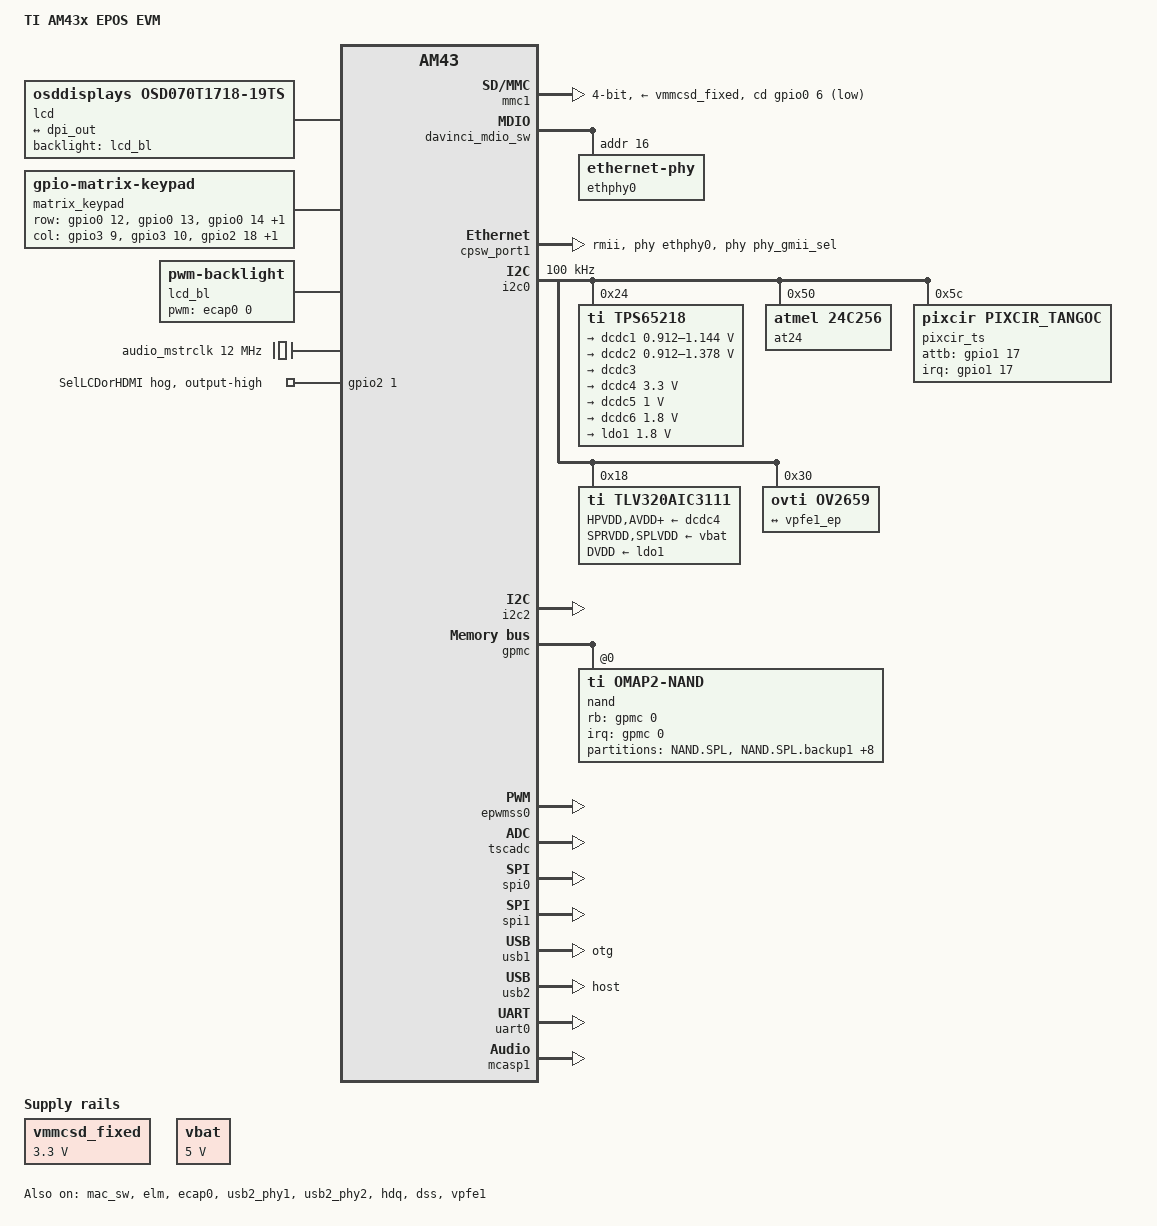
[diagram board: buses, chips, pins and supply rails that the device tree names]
/dts-v1/;
#include "am4372.dtsi"
#include <dt-bindings/pinctrl/am43xx.h>
#include <dt-bindings/gpio/gpio.h>
#include <dt-bindings/pwm/pwm.h>
#include <dt-bindings/sound/tlv320aic31xx.h>
/ {
	model = "TI AM43x EPOS EVM";
	compatible = "ti,am43x-epos-evm","ti,am438x","ti,am43";
	aliases {
		display0 = &lcd0;
	};
	chosen {
		stdout-path = &uart0;
	};
	vmmcsd_fixed: fixedregulator-sd {
		compatible = "regulator-fixed";
		regulator-name = "vmmcsd_fixed";
		regulator-min-microvolt = <3300000>;
		regulator-max-microvolt = <3300000>;
		enable-active-high;
	};
	vbat: fixedregulator0 {
		compatible = "regulator-fixed";
		regulator-name = "vbat";
		regulator-min-microvolt = <5000000>;
		regulator-max-microvolt = <5000000>;
		regulator-boot-on;
	};
	lcd0: display {
		compatible = "osddisplays,osd070t1718-19ts", "panel-dpi";
		label = "lcd";
		backlight = <&lcd_bl>;
		port {
			lcd_in: endpoint {
				remote-endpoint = <&dpi_out>;
			};
		};
	};
	matrix_keypad: matrix_keypad0 {
		compatible = "gpio-matrix-keypad";
		debounce-delay-ms = <5>;
		col-scan-delay-us = <2>;
		pinctrl-names = "default", "sleep";
		pinctrl-0 = <&matrix_keypad_default>;
		pinctrl-1 = <&matrix_keypad_sleep>;
		wakeup-source;
		row-gpios = <&gpio0 12 GPIO_ACTIVE_HIGH		 
			     &gpio0 13 GPIO_ACTIVE_HIGH		 
			     &gpio0 14 GPIO_ACTIVE_HIGH		 
			     &gpio0 15 GPIO_ACTIVE_HIGH>;	 
		col-gpios = <&gpio3 9 GPIO_ACTIVE_HIGH		 
			     &gpio3 10 GPIO_ACTIVE_HIGH		 
			     &gpio2 18 GPIO_ACTIVE_HIGH		 
			     &gpio2 19 GPIO_ACTIVE_HIGH>;	 
		linux,keymap = <0x00000201	 
			0x01000204	 
			0x02000207	 
			0x0300020a	 
			0x00010202	 
			0x01010205	 
			0x02010208	 
			0x03010200	 
			0x00020203	 
			0x01020206	 
			0x02020209	 
			0x0302020b	 
			0x00030067	 
			0x0103006a	 
			0x0203006c	 
			0x03030069>;	 
	};
	lcd_bl: backlight {
		compatible = "pwm-backlight";
		pwms = <&ecap0 0 50000 PWM_POLARITY_INVERTED>;
		brightness-levels = <0 51 53 56 62 75 101 152 255>;
		default-brightness-level = <8>;
	};
	sound0: sound0 {
		compatible = "simple-audio-card";
		simple-audio-card,name = "AM43-EPOS-EVM";
		simple-audio-card,widgets =
			"Microphone", "Microphone Jack",
			"Headphone", "Headphone Jack",
			"Speaker", "Speaker";
		simple-audio-card,routing =
			"MIC1LP", "Microphone Jack",
			"MIC1RP", "Microphone Jack",
			"MIC1LP", "MICBIAS",
			"MIC1RP", "MICBIAS",
			"Headphone Jack", "HPL",
			"Headphone Jack", "HPR",
			"Speaker", "SPL",
			"Speaker", "SPR";
		simple-audio-card,format = "dsp_b";
		simple-audio-card,bitclock-master = <&sound0_master>;
		simple-audio-card,frame-master = <&sound0_master>;
		simple-audio-card,bitclock-inversion;
		simple-audio-card,cpu {
			sound-dai = <&mcasp1>;
			system-clock-frequency = <12000000>;
		};
		sound0_master: simple-audio-card,codec {
			sound-dai = <&tlv320aic3111>;
			system-clock-frequency = <12000000>;
		};
	};
	audio_mstrclk: clock {
		compatible = "fixed-clock";
		#clock-cells = <0>;
		clock-frequency = <12000000>;
	};
};
&am43xx_pinmux {
		pinctrl-names = "default";
		pinctrl-0 = <&unused_pins>;
		unused_pins: unused-pins {
			pinctrl-single,pins = <
				AM4372_IOPAD(0x848, DS0_PIN_OUTPUT_PULLUP | PIN_OUTPUT_PULLUP | MUX_MODE7)
				AM4372_IOPAD(0x850, DS0_PIN_INPUT | PIN_INPUT_PULLDOWN | MUX_MODE7)
				AM4372_IOPAD(0x858, DS0_PIN_INPUT | PIN_INPUT_PULLDOWN | MUX_MODE7)
				AM4372_IOPAD(0x860, DS0_PIN_INPUT | PIN_INPUT_PULLDOWN | MUX_MODE7)
				AM4372_IOPAD(0x864, DS0_PIN_INPUT | PIN_INPUT_PULLDOWN | MUX_MODE7)
				AM4372_IOPAD(0x868, DS0_PIN_INPUT | PIN_INPUT_PULLDOWN | MUX_MODE7)
				AM4372_IOPAD(0x86c, DS0_PIN_INPUT | PIN_INPUT_PULLDOWN | MUX_MODE7)
				AM4372_IOPAD(0x878, DS0_PIN_OUTPUT_PULLUP | PIN_OUTPUT_PULLUP | MUX_MODE7)
				AM4372_IOPAD(0x908, DS0_PIN_INPUT_PULLDOWN | PIN_INPUT_PULLDOWN | MUX_MODE7)
				AM4372_IOPAD(0x91c, DS0_PIN_OUTPUT_PULLDOWN | PIN_OUTPUT_PULLDOWN | MUX_MODE7)
				AM4372_IOPAD(0x920, DS0_PIN_INPUT | PIN_INPUT_PULLDOWN | MUX_MODE7)
				AM4372_IOPAD(0x9e0, DS0_PIN_INPUT_PULLDOWN | PIN_INPUT_PULLDOWN | MUX_MODE7)
				AM4372_IOPAD(0xA0c, DS0_PIN_OUTPUT_PULLDOWN | PIN_OUTPUT_PULLDOWN | MUX_MODE7)
				AM4372_IOPAD(0xA38, DS0_PIN_INPUT | PIN_INPUT_PULLDOWN | MUX_MODE7)
				AM4372_IOPAD(0xA3c, DS0_PIN_INPUT | PIN_INPUT_PULLDOWN | MUX_MODE7)
				AM4372_IOPAD(0xA40, DS0_PIN_INPUT | PIN_INPUT_PULLDOWN | MUX_MODE7)
				AM4372_IOPAD(0xA44, DS0_PIN_INPUT | PIN_INPUT_PULLDOWN | MUX_MODE7)
				AM4372_IOPAD(0xA48, DS0_PIN_INPUT | PIN_INPUT_PULLDOWN | MUX_MODE7)
				AM4372_IOPAD(0xA4c, DS0_PIN_INPUT | PIN_INPUT_PULLDOWN | MUX_MODE7)
				AM4372_IOPAD(0xA50, DS0_PIN_INPUT | PIN_INPUT_PULLDOWN | MUX_MODE7)
				AM4372_IOPAD(0xA54, DS0_PIN_INPUT | PIN_INPUT_PULLDOWN | MUX_MODE7)
				AM4372_IOPAD(0xA58, DS0_PIN_INPUT | PIN_INPUT_PULLDOWN | MUX_MODE7)
				AM4372_IOPAD(0xA5c, DS0_PIN_INPUT | PIN_INPUT_PULLDOWN | MUX_MODE7)
				AM4372_IOPAD(0xA60, DS0_PIN_INPUT | PIN_INPUT_PULLDOWN | MUX_MODE7)
				AM4372_IOPAD(0xA64, DS0_PIN_OUTPUT_PULLUP | PIN_OUTPUT_PULLUP | MUX_MODE7)
				AM4372_IOPAD(0xA68, DS0_PIN_INPUT | PIN_INPUT_PULLDOWN | MUX_MODE7)
				AM4372_IOPAD(0xA6C, DS0_PIN_INPUT | PIN_INPUT_PULLDOWN | MUX_MODE7)
				AM4372_IOPAD(0xA74, DS0_PIN_INPUT_PULLDOWN | PIN_INPUT_PULLDOWN | MUX_MODE7)
				AM4372_IOPAD(0xA78, DS0_PIN_INPUT | PIN_INPUT_PULLDOWN | MUX_MODE7)
			>;
		};
		cpsw_default: cpsw-default-pins {
			pinctrl-single,pins = <
				AM4372_IOPAD(0x90c, PIN_INPUT_PULLDOWN | MUX_MODE1)	 
				AM4372_IOPAD(0x910, PIN_INPUT_PULLDOWN | MUX_MODE1)	 
				AM4372_IOPAD(0x914, PIN_OUTPUT_PULLDOWN | MUX_MODE1)	 
				AM4372_IOPAD(0x918, PIN_INPUT_PULLDOWN | MUX_MODE1)	 
				AM4372_IOPAD(0x924, PIN_OUTPUT_PULLDOWN | MUX_MODE1)	 
				AM4372_IOPAD(0x928, PIN_OUTPUT_PULLDOWN | MUX_MODE1)	 
				AM4372_IOPAD(0x93c, PIN_INPUT_PULLDOWN | MUX_MODE1)	 
				AM4372_IOPAD(0x940, PIN_INPUT_PULLDOWN | MUX_MODE1)	 
				AM4372_IOPAD(0x944, PIN_INPUT_PULLDOWN | MUX_MODE0)	 
			>;
		};
		cpsw_sleep: cpsw-sleep-pins {
			pinctrl-single,pins = <
				AM4372_IOPAD(0x90c, PIN_INPUT_PULLDOWN | MUX_MODE7)
				AM4372_IOPAD(0x910, PIN_INPUT_PULLDOWN | MUX_MODE7)
				AM4372_IOPAD(0x914, PIN_INPUT_PULLDOWN | MUX_MODE7)
				AM4372_IOPAD(0x918, PIN_INPUT_PULLDOWN | MUX_MODE7)
				AM4372_IOPAD(0x924, PIN_INPUT_PULLDOWN | MUX_MODE7)
				AM4372_IOPAD(0x928, PIN_INPUT_PULLDOWN | MUX_MODE7)
				AM4372_IOPAD(0x93c, PIN_INPUT_PULLDOWN | MUX_MODE7)
				AM4372_IOPAD(0x940, PIN_INPUT_PULLDOWN | MUX_MODE7)
				AM4372_IOPAD(0x944, PIN_INPUT_PULLDOWN | MUX_MODE7)
			>;
		};
		davinci_mdio_default: davinci-mdio-default-pins {
			pinctrl-single,pins = <
				AM4372_IOPAD(0x948, PIN_INPUT_PULLUP | SLEWCTRL_FAST | MUX_MODE0)	 
				AM4372_IOPAD(0x94c, PIN_OUTPUT_PULLUP | MUX_MODE0)			 
			>;
		};
		davinci_mdio_sleep: davinci-mdio-sleep-pins {
			pinctrl-single,pins = <
				AM4372_IOPAD(0x948, PIN_INPUT_PULLDOWN | MUX_MODE7)
				AM4372_IOPAD(0x94c, PIN_INPUT_PULLDOWN | MUX_MODE7)
			>;
		};
		i2c0_pins: i2c0-pins {
			pinctrl-single,pins = <
				AM4372_IOPAD(0x988, PIN_INPUT_PULLUP | SLEWCTRL_FAST | MUX_MODE0)	 
				AM4372_IOPAD(0x98c, PIN_INPUT_PULLUP | SLEWCTRL_FAST | MUX_MODE0)	 
			>;
		};
		nand_flash_x8_default: nand-flash-x8-default-pins {
			pinctrl-single,pins = <
				AM4372_IOPAD(0x840, PIN_OUTPUT_PULLDOWN | MUX_MODE7)	 
				AM4372_IOPAD(0x800, PIN_INPUT_PULLDOWN | MUX_MODE0)	 
				AM4372_IOPAD(0x804, PIN_INPUT_PULLDOWN | MUX_MODE0)	 
				AM4372_IOPAD(0x808, PIN_INPUT_PULLDOWN | MUX_MODE0)	 
				AM4372_IOPAD(0x80c, PIN_INPUT_PULLDOWN | MUX_MODE0)	 
				AM4372_IOPAD(0x810, PIN_INPUT_PULLDOWN | MUX_MODE0)	 
				AM4372_IOPAD(0x814, PIN_INPUT_PULLDOWN | MUX_MODE0)	 
				AM4372_IOPAD(0x818, PIN_INPUT_PULLDOWN | MUX_MODE0)	 
				AM4372_IOPAD(0x81c, PIN_INPUT_PULLDOWN | MUX_MODE0)	 
				AM4372_IOPAD(0x870, PIN_INPUT_PULLUP | MUX_MODE0)	 
				AM4372_IOPAD(0x874, PIN_OUTPUT_PULLUP | MUX_MODE7)	 
				AM4372_IOPAD(0x87c, PIN_OUTPUT | MUX_MODE0)		 
				AM4372_IOPAD(0x890, PIN_OUTPUT | MUX_MODE0)		 
				AM4372_IOPAD(0x894, PIN_OUTPUT | MUX_MODE0)		 
				AM4372_IOPAD(0x898, PIN_OUTPUT | MUX_MODE0)		 
				AM4372_IOPAD(0x89c, PIN_OUTPUT | MUX_MODE0)		 
			>;
		};
		nand_flash_x8_sleep: nand-flash-x8-sleep-pins {
			pinctrl-single,pins = <
				AM4372_IOPAD(0x840, DS0_PIN_OUTPUT_PULLDOWN | MUX_MODE7)
				AM4372_IOPAD(0x800, DS0_PIN_OUTPUT_PULLDOWN | MUX_MODE7)
				AM4372_IOPAD(0x804, DS0_PIN_OUTPUT_PULLDOWN | MUX_MODE7)
				AM4372_IOPAD(0x808, DS0_PIN_OUTPUT_PULLDOWN | MUX_MODE7)
				AM4372_IOPAD(0x80c, DS0_PIN_OUTPUT_PULLDOWN | MUX_MODE7)
				AM4372_IOPAD(0x810, DS0_PIN_OUTPUT_PULLDOWN | MUX_MODE7)
				AM4372_IOPAD(0x814, DS0_PIN_OUTPUT_PULLDOWN | MUX_MODE7)
				AM4372_IOPAD(0x818, DS0_PIN_OUTPUT_PULLDOWN | MUX_MODE7)
				AM4372_IOPAD(0x81c, DS0_PIN_OUTPUT_PULLDOWN | MUX_MODE7)
				AM4372_IOPAD(0x870, DS0_PIN_OUTPUT_PULLUP | MUX_MODE7)
				AM4372_IOPAD(0x874, DS0_PIN_OUTPUT_PULLUP | MUX_MODE7)
				AM4372_IOPAD(0x87c, DS0_PIN_OUTPUT_PULLUP | MUX_MODE7)
				AM4372_IOPAD(0x890, DS0_PIN_OUTPUT_PULLUP | MUX_MODE7)
				AM4372_IOPAD(0x894, DS0_PIN_OUTPUT_PULLUP | MUX_MODE7)
				AM4372_IOPAD(0x898, DS0_PIN_OUTPUT_PULLUP | MUX_MODE7)
				AM4372_IOPAD(0x89c, DS0_PIN_OUTPUT_PULLUP | MUX_MODE7)
			>;
		};
		ecap0_pins_default: backlight-default-pins {
			pinctrl-single,pins = <
				AM4372_IOPAD(0x964, MUX_MODE0)          
			>;
		};
		ecap0_pins_sleep: backlight-sleep-pins {
			pinctrl-single,pins = <
				AM4372_IOPAD(0x964, DS0_PIN_OUTPUT_PULLUP | MUX_MODE7)
			>;
		};
		i2c2_pins: i2c2-pins {
			pinctrl-single,pins = <
				AM4372_IOPAD(0x9c0, PIN_INPUT_PULLUP | SLEWCTRL_FAST | MUX_MODE8)     
				AM4372_IOPAD(0x9c4, PIN_INPUT_PULLUP | SLEWCTRL_FAST | MUX_MODE8)     
			>;
		};
		spi0_pins_default: spi0-default-pins {
			pinctrl-single,pins = <
				AM4372_IOPAD(0x950, PIN_INPUT | MUX_MODE0)            
				AM4372_IOPAD(0x954, PIN_OUTPUT | MUX_MODE0)            
				AM4372_IOPAD(0x958, PIN_INPUT | MUX_MODE0)            
				AM4372_IOPAD(0x95c, PIN_OUTPUT | MUX_MODE0)           
			>;
		};
		spi0_pins_sleep: spi0-sleep-pins {
			pinctrl-single,pins = <
				AM4372_IOPAD(0x950, DS0_PIN_OUTPUT_PULLUP | PIN_OUTPUT_PULLUP | MUX_MODE7)
				AM4372_IOPAD(0x954, DS0_PIN_OUTPUT_PULLUP | PIN_OUTPUT_PULLUP | MUX_MODE7)
				AM4372_IOPAD(0x958, DS0_PIN_OUTPUT_PULLUP | PIN_OUTPUT_PULLUP | MUX_MODE7)
				AM4372_IOPAD(0x95c, DS0_PIN_OUTPUT_PULLUP | PIN_OUTPUT_PULLUP | MUX_MODE7)
			>;
		};
		spi1_pins_default: spi1-default-pins {
			pinctrl-single,pins = <
				AM4372_IOPAD(0x990, PIN_INPUT | MUX_MODE3)            
				AM4372_IOPAD(0x994, PIN_OUTPUT | MUX_MODE3)            
				AM4372_IOPAD(0x998, PIN_INPUT | MUX_MODE3)            
				AM4372_IOPAD(0x99c, PIN_OUTPUT | MUX_MODE3)           
			>;
		};
		spi1_pins_sleep: spi1-sleep-pins {
			pinctrl-single,pins = <
				AM4372_IOPAD(0x990, DS0_PIN_OUTPUT_PULLDOWN | PIN_OUTPUT_PULLDOWN | MUX_MODE7)
				AM4372_IOPAD(0x994, DS0_PIN_OUTPUT_PULLDOWN | PIN_OUTPUT_PULLDOWN | MUX_MODE7)
				AM4372_IOPAD(0x998, DS0_PIN_OUTPUT_PULLDOWN | PIN_OUTPUT_PULLDOWN | MUX_MODE7)
				AM4372_IOPAD(0x99c, DS0_PIN_OUTPUT_PULLDOWN | PIN_OUTPUT_PULLDOWN | MUX_MODE7)
			>;
		};
		mmc1_pins_default: mmc1-default-pins {
			pinctrl-single,pins = <
				AM4372_IOPAD(0x960, PIN_INPUT | MUX_MODE7)  
			>;
		};
		mmc1_pins_sleep: mmc1-sleep-pins {
			pinctrl-single,pins = <
				AM4372_IOPAD(0x960, DS0_PIN_OUTPUT_PULLUP | PIN_INPUT | MUX_MODE7)
			>;
		};
		matrix_keypad_default: matrix-keypad-default-pins {
			pinctrl-single,pins = <
				 AM4372_IOPAD(0x92c, PIN_OUTPUT | MUX_MODE7)           
				 AM4372_IOPAD(0x930, PIN_OUTPUT | MUX_MODE7)           
				 AM4372_IOPAD(0x934, PIN_OUTPUT | MUX_MODE7)           
				 AM4372_IOPAD(0x938, PIN_OUTPUT | MUX_MODE7)           
				 AM4372_IOPAD(0x978, PIN_INPUT_PULLDOWN | MUX_MODE7)   
				 AM4372_IOPAD(0x97C, PIN_INPUT_PULLDOWN | MUX_MODE7)   
				 AM4372_IOPAD(0x980, PIN_INPUT_PULLDOWN | MUX_MODE7)   
				 AM4372_IOPAD(0x984, PIN_INPUT_PULLDOWN | MUX_MODE7)   
			>;
		};
		matrix_keypad_sleep: matrix-keypad-sleep-pins {
			pinctrl-single,pins = <
				AM4372_IOPAD(0x92c, PIN_INPUT_PULLUP | MUX_MODE7)
				AM4372_IOPAD(0x930, PIN_INPUT_PULLUP | MUX_MODE7)
				AM4372_IOPAD(0x934, PIN_INPUT_PULLUP | MUX_MODE7)
				AM4372_IOPAD(0x938, PIN_INPUT_PULLUP | MUX_MODE7)
				AM4372_IOPAD(0x978, PIN_INPUT_PULLDOWN | MUX_MODE7)
				AM4372_IOPAD(0x97C, PIN_INPUT_PULLDOWN | MUX_MODE7)
				AM4372_IOPAD(0x980, PIN_INPUT_PULLDOWN | MUX_MODE7)
				AM4372_IOPAD(0x984, PIN_INPUT_PULLDOWN | MUX_MODE7)
			>;
		};
		qspi1_pins_default: qspi1-default-pins {
			pinctrl-single,pins = <
				AM4372_IOPAD(0x87c, PIN_INPUT_PULLUP | MUX_MODE3)
				AM4372_IOPAD(0x888, PIN_INPUT_PULLUP | MUX_MODE2)
				AM4372_IOPAD(0x890, PIN_INPUT_PULLUP | MUX_MODE3)
				AM4372_IOPAD(0x894, PIN_INPUT_PULLUP | MUX_MODE3)
				AM4372_IOPAD(0x898, PIN_INPUT_PULLUP | MUX_MODE3)
				AM4372_IOPAD(0x89c, PIN_INPUT_PULLUP | MUX_MODE3)
			>;
		};
		qspi1_pins_sleep: qspi1-sleep-pins {
			pinctrl-single,pins = <
				AM4372_IOPAD(0x87c, DS0_PIN_OUTPUT_PULLUP | MUX_MODE7)
				AM4372_IOPAD(0x888, DS0_PIN_OUTPUT_PULLUP | MUX_MODE7)
				AM4372_IOPAD(0x890, DS0_PIN_OUTPUT_PULLUP | MUX_MODE7)
				AM4372_IOPAD(0x894, DS0_PIN_OUTPUT_PULLUP | MUX_MODE7)
				AM4372_IOPAD(0x898, DS0_PIN_OUTPUT_PULLUP | MUX_MODE7)
				AM4372_IOPAD(0x89c, DS0_PIN_OUTPUT_PULLUP | MUX_MODE7)
			>;
		};
		pixcir_ts_pins_default: pixcir-ts-default-pins {
			pinctrl-single,pins = <
				AM4372_IOPAD(0x844, PIN_INPUT_PULLUP | MUX_MODE7)	 
			>;
		};
		pixcir_ts_pins_sleep: pixcir-ts-sleep-pins {
			pinctrl-single,pins = <
				AM4372_IOPAD(0x844, DS0_PIN_OUTPUT_PULLUP | PIN_OUTPUT_PULLUP | MUX_MODE7)	 
			>;
		};
		hdq_pins: hdq-pins {
			pinctrl-single,pins = <
				AM4372_IOPAD(0xa34, PIN_INPUT_PULLUP | MUX_MODE1)     
			>;
		};
		dss_pins: dss-pins {
			pinctrl-single,pins = <
				AM4372_IOPAD(0x820, PIN_OUTPUT_PULLUP | MUX_MODE1)  
				AM4372_IOPAD(0x824, PIN_OUTPUT_PULLUP | MUX_MODE1)
				AM4372_IOPAD(0x828, PIN_OUTPUT_PULLUP | MUX_MODE1)
				AM4372_IOPAD(0x82c, PIN_OUTPUT_PULLUP | MUX_MODE1)
				AM4372_IOPAD(0x830, PIN_OUTPUT_PULLUP | MUX_MODE1)
				AM4372_IOPAD(0x834, PIN_OUTPUT_PULLUP | MUX_MODE1)
				AM4372_IOPAD(0x838, PIN_OUTPUT_PULLUP | MUX_MODE1)
				AM4372_IOPAD(0x83c, PIN_OUTPUT_PULLUP | MUX_MODE1)  
				AM4372_IOPAD(0x8a0, PIN_OUTPUT_PULLUP | MUX_MODE0)  
				AM4372_IOPAD(0x8a4, PIN_OUTPUT_PULLUP | MUX_MODE0)
				AM4372_IOPAD(0x8a8, PIN_OUTPUT_PULLUP | MUX_MODE0)
				AM4372_IOPAD(0x8ac, PIN_OUTPUT_PULLUP | MUX_MODE0)
				AM4372_IOPAD(0x8b0, PIN_OUTPUT_PULLUP | MUX_MODE0)
				AM4372_IOPAD(0x8b4, PIN_OUTPUT_PULLUP | MUX_MODE0)
				AM4372_IOPAD(0x8B8, PIN_OUTPUT_PULLUP | MUX_MODE0)
				AM4372_IOPAD(0x8bc, PIN_OUTPUT_PULLUP | MUX_MODE0)
				AM4372_IOPAD(0x8c0, PIN_OUTPUT_PULLUP | MUX_MODE0)
				AM4372_IOPAD(0x8c4, PIN_OUTPUT_PULLUP | MUX_MODE0)
				AM4372_IOPAD(0x8c8, PIN_OUTPUT_PULLUP | MUX_MODE0)
				AM4372_IOPAD(0x8cc, PIN_OUTPUT_PULLUP | MUX_MODE0)
				AM4372_IOPAD(0x8d0, PIN_OUTPUT_PULLUP | MUX_MODE0)
				AM4372_IOPAD(0x8d4, PIN_OUTPUT_PULLUP | MUX_MODE0)
				AM4372_IOPAD(0x8d8, PIN_OUTPUT_PULLUP | MUX_MODE0)
				AM4372_IOPAD(0x8dc, PIN_OUTPUT_PULLUP | MUX_MODE0)  
				AM4372_IOPAD(0x8e0, PIN_OUTPUT_PULLUP | MUX_MODE0)  
				AM4372_IOPAD(0x8e4, PIN_OUTPUT_PULLUP | MUX_MODE0)  
				AM4372_IOPAD(0x8e8, PIN_OUTPUT_PULLUP | MUX_MODE0)  
				AM4372_IOPAD(0x8ec, PIN_OUTPUT_PULLUP | MUX_MODE0)  
			>;
		};
		display_mux_pins: display-mux-pins {
			pinctrl-single,pins = <
				AM4372_IOPAD(0x88C, PIN_OUTPUT_PULLUP | MUX_MODE7)
			>;
		};
		vpfe1_pins_default: vpfe1-default-pins {
			pinctrl-single,pins = <
				AM4372_IOPAD(0x9cc, PIN_INPUT_PULLUP | MUX_MODE0)   
				AM4372_IOPAD(0x9d0, PIN_INPUT_PULLUP | MUX_MODE0)   
				AM4372_IOPAD(0x9d4, PIN_INPUT_PULLUP | MUX_MODE0)   
				AM4372_IOPAD(0x9d8, PIN_INPUT_PULLUP | MUX_MODE0)   
				AM4372_IOPAD(0x9dc, PIN_INPUT_PULLUP | MUX_MODE0)   
				AM4372_IOPAD(0x9e8, PIN_INPUT_PULLUP | MUX_MODE0)   
				AM4372_IOPAD(0x9ec, PIN_INPUT_PULLUP | MUX_MODE0)   
				AM4372_IOPAD(0x9f0, PIN_INPUT_PULLUP | MUX_MODE0)   
				AM4372_IOPAD(0x9f4, PIN_INPUT_PULLUP | MUX_MODE0)   
				AM4372_IOPAD(0x9f8, PIN_INPUT_PULLUP | MUX_MODE0)   
				AM4372_IOPAD(0x9fc, PIN_INPUT_PULLUP | MUX_MODE0)   
				AM4372_IOPAD(0xa00, PIN_INPUT_PULLUP | MUX_MODE0)   
				AM4372_IOPAD(0xa04, PIN_INPUT_PULLUP | MUX_MODE0)   
			>;
		};
		vpfe1_pins_sleep: vpfe1-sleep-pins {
			pinctrl-single,pins = <
				AM4372_IOPAD(0x9cc, DS0_PULL_UP_DOWN_EN | INPUT_EN | MUX_MODE7)
				AM4372_IOPAD(0x9d0, DS0_PULL_UP_DOWN_EN | INPUT_EN | MUX_MODE7)
				AM4372_IOPAD(0x9d4, DS0_PULL_UP_DOWN_EN | INPUT_EN | MUX_MODE7)
				AM4372_IOPAD(0x9d8, DS0_PULL_UP_DOWN_EN | INPUT_EN | MUX_MODE7)
				AM4372_IOPAD(0x9dc, DS0_PULL_UP_DOWN_EN | INPUT_EN | MUX_MODE7)
				AM4372_IOPAD(0x9e8, DS0_PULL_UP_DOWN_EN | INPUT_EN | MUX_MODE7)
				AM4372_IOPAD(0x9ec, DS0_PULL_UP_DOWN_EN | INPUT_EN | MUX_MODE7)
				AM4372_IOPAD(0x9f0, DS0_PULL_UP_DOWN_EN | INPUT_EN | MUX_MODE7)
				AM4372_IOPAD(0x9f4, DS0_PULL_UP_DOWN_EN | INPUT_EN | MUX_MODE7)
				AM4372_IOPAD(0x9f8, DS0_PULL_UP_DOWN_EN | INPUT_EN | MUX_MODE7)
				AM4372_IOPAD(0x9fc, DS0_PULL_UP_DOWN_EN | INPUT_EN | MUX_MODE7)
				AM4372_IOPAD(0xa00, DS0_PULL_UP_DOWN_EN | INPUT_EN | MUX_MODE7)
				AM4372_IOPAD(0xa04, DS0_PULL_UP_DOWN_EN | INPUT_EN | MUX_MODE7)
			>;
		};
		uart0_pins_default: uart0-default-pins {
			pinctrl-single,pins = <
				AM4372_IOPAD(0x968, DS0_PULL_UP_DOWN_EN | INPUT_EN | MUX_MODE0)  
				AM4372_IOPAD(0x96C, DS0_PULL_UP_DOWN_EN | INPUT_EN | MUX_MODE0)  
				AM4372_IOPAD(0x970, PIN_INPUT_PULLUP | SLEWCTRL_FAST | DS0_PULL_UP_DOWN_EN | MUX_MODE0)	 
				AM4372_IOPAD(0x974, PIN_INPUT | SLEWCTRL_FAST | DS0_PULL_UP_DOWN_EN | MUX_MODE0)	 
			>;
		};
		uart0_pins_sleep: uart0-sleep-pins {
			pinctrl-single,pins = <
				AM4372_IOPAD(0x968, DS0_PULL_UP_DOWN_EN | INPUT_EN | MUX_MODE7)
				AM4372_IOPAD(0x96C, DS0_PULL_UP_DOWN_EN | INPUT_EN | MUX_MODE7)
				AM4372_IOPAD(0x970, PIN_INPUT_PULLUP | SLEWCTRL_FAST | DS0_PULL_UP_DOWN_EN | MUX_MODE0)
				AM4372_IOPAD(0x974, PIN_INPUT | SLEWCTRL_FAST | DS0_PULL_UP_DOWN_EN | MUX_MODE0)
			>;
		};
		usb2_phy1_default: usb2-phy1-default-pins {
			pinctrl-single,pins = <
				AM4372_IOPAD(0xac0, PIN_INPUT_PULLDOWN | MUX_MODE0)
			>;
		};
		usb2_phy1_sleep: usb2-phy1-sleep-pins {
			pinctrl-single,pins = <
				AM4372_IOPAD(0xac0, DS0_PULL_UP_DOWN_EN | PIN_INPUT_PULLDOWN | MUX_MODE7)
			>;
		};
		usb2_phy2_default: usb2-phy2-default-pins {
			pinctrl-single,pins = <
				AM4372_IOPAD(0xac4, PIN_INPUT_PULLDOWN | MUX_MODE0)
			>;
		};
		usb2_phy2_sleep: usb2-phy2-sleep-pins {
			pinctrl-single,pins = <
				AM4372_IOPAD(0xac4, DS0_PULL_UP_DOWN_EN | PIN_INPUT_PULLDOWN | MUX_MODE7)
			>;
		};
		mcasp1_pins: mcasp1-pins {
			pinctrl-single,pins = <
				AM4372_IOPAD(0x9a0, PIN_INPUT_PULLDOWN | MUX_MODE3)  
				AM4372_IOPAD(0x9a4, PIN_INPUT_PULLDOWN | MUX_MODE3)  
				AM4372_IOPAD(0x9a8, PIN_OUTPUT_PULLDOWN | MUX_MODE3) 
				AM4372_IOPAD(0x9ac, PIN_INPUT_PULLDOWN | MUX_MODE3)  
			>;
		};
		mcasp1_sleep_pins: mcasp1-sleep-pins {
			pinctrl-single,pins = <
				AM4372_IOPAD(0x9a0, PIN_INPUT_PULLDOWN | MUX_MODE7)
				AM4372_IOPAD(0x9a4, PIN_INPUT_PULLDOWN | MUX_MODE7)
				AM4372_IOPAD(0x9a8, PIN_INPUT_PULLDOWN | MUX_MODE7)
				AM4372_IOPAD(0x9ac, PIN_INPUT_PULLDOWN | MUX_MODE7)
			>;
		};
};
&mmc1 {
	status = "okay";
	vmmc-supply = <&vmmcsd_fixed>;
	bus-width = <4>;
	pinctrl-names = "default", "sleep";
	pinctrl-0 = <&mmc1_pins_default>;
	pinctrl-1 = <&mmc1_pins_sleep>;
	cd-gpios = <&gpio0 6 GPIO_ACTIVE_LOW>;
};
&mac_sw {
	pinctrl-names = "default", "sleep";
	pinctrl-0 = <&cpsw_default>;
	pinctrl-1 = <&cpsw_sleep>;
	status = "okay";
};
&davinci_mdio_sw {
	pinctrl-names = "default", "sleep";
	pinctrl-0 = <&davinci_mdio_default>;
	pinctrl-1 = <&davinci_mdio_sleep>;
	ethphy0: ethernet-phy@16 {
		reg = <16>;
	};
};
&cpsw_port1 {
	phy-handle = <&ethphy0>;
	phy-mode = "rmii";
	phys = <&phy_gmii_sel 1 1>;
	ti,dual-emac-pvid = <1>;
};
&cpsw_port2 {
	status = "disabled";
};
&i2c0 {
	status = "okay";
	pinctrl-names = "default";
	pinctrl-0 = <&i2c0_pins>;
	clock-frequency = <100000>;
	tps65218: tps65218@24 {
		reg = <0x24>;
		compatible = "ti,tps65218";
		interrupts = <GIC_SPI 7 IRQ_TYPE_LEVEL_HIGH>;  
		interrupt-controller;
		#interrupt-cells = <2>;
		dcdc1: regulator-dcdc1 {
			regulator-name = "vdd_core";
			regulator-min-microvolt = <912000>;
			regulator-max-microvolt = <1144000>;
			regulator-boot-on;
			regulator-always-on;
		};
		dcdc2: regulator-dcdc2 {
			regulator-name = "vdd_mpu";
			regulator-min-microvolt = <912000>;
			regulator-max-microvolt = <1378000>;
			regulator-boot-on;
			regulator-always-on;
		};
		dcdc3: regulator-dcdc3 {
			regulator-name = "vdcdc3";
			regulator-boot-on;
			regulator-always-on;
			regulator-state-mem {
				regulator-on-in-suspend;
			};
			regulator-state-disk {
				regulator-off-in-suspend;
			};
		};
		dcdc4: regulator-dcdc4 {
			regulator-name = "vdcdc4";
			regulator-min-microvolt = <3300000>;
			regulator-max-microvolt = <3300000>;
			regulator-boot-on;
			regulator-always-on;
		};
		dcdc5: regulator-dcdc5 {
			regulator-name = "v1_0bat";
			regulator-min-microvolt = <1000000>;
			regulator-max-microvolt = <1000000>;
			regulator-boot-on;
			regulator-always-on;
		};
		dcdc6: regulator-dcdc6 {
			regulator-name = "v1_8bat";
			regulator-min-microvolt = <1800000>;
			regulator-max-microvolt = <1800000>;
			regulator-boot-on;
			regulator-always-on;
		};
		ldo1: regulator-ldo1 {
			regulator-min-microvolt = <1800000>;
			regulator-max-microvolt = <1800000>;
			regulator-boot-on;
			regulator-always-on;
		};
	};
	at24@50 {
		compatible = "atmel,24c256";
		pagesize = <64>;
		reg = <0x50>;
	};
	pixcir_ts@5c {
		compatible = "pixcir,pixcir_tangoc";
		pinctrl-names = "default", "sleep";
		pinctrl-0 = <&pixcir_ts_pins_default>;
		pinctrl-1 = <&pixcir_ts_pins_sleep>;
		reg = <0x5c>;
		interrupt-parent = <&gpio1>;
		interrupts = <17 IRQ_TYPE_EDGE_FALLING>;
		attb-gpio = <&gpio1 17 GPIO_ACTIVE_HIGH>;
		touchscreen-size-x = <1024>;
		touchscreen-size-y = <600>;
	};
	tlv320aic3111: tlv320aic3111@18 {
		#sound-dai-cells = <0>;
		compatible = "ti,tlv320aic3111";
		reg = <0x18>;
		status = "okay";
		ai31xx-micbias-vg = <MICBIAS_2_0V>;
		HPVDD-supply = <&dcdc4>;  
		SPRVDD-supply = <&vbat>;  
		SPLVDD-supply = <&vbat>;  
		AVDD-supply = <&dcdc4>;  
		IOVDD-supply = <&dcdc4>;  
		DVDD-supply = <&ldo1>;  
	};
	ov2659@30 {
		compatible = "ovti,ov2659";
		reg = <0x30>;
		clocks = <&audio_mstrclk>;
		clock-names = "xvclk";
		port {
			ov2659_1: endpoint {
				remote-endpoint = <&vpfe1_ep>;
				link-frequencies = /bits/ 64 <70000000>;
			};
		};
	};
};
&i2c2 {
	pinctrl-names = "default";
	pinctrl-0 = <&i2c2_pins>;
	status = "okay";
};
&gpio0 {
	status = "okay";
};
&gpio1 {
	status = "okay";
};
&gpio2 {
	pinctrl-names = "default";
	pinctrl-0 = <&display_mux_pins>;
	status = "okay";
	sel-lcd-hdmi-hog {
		gpio-hog;
		gpios = <1 GPIO_ACTIVE_HIGH>;
		output-high;
		line-name = "SelLCDorHDMI";
	};
};
&gpio3 {
	status = "okay";
};
&elm {
	status = "okay";
};
&gpmc {
	status = "okay";	 
	pinctrl-names = "default", "sleep";
	pinctrl-0 = <&nand_flash_x8_default>;
	pinctrl-1 = <&nand_flash_x8_sleep>;
	ranges = <0 0 0x08000000 0x01000000>;	 
	nand@0,0 {
		compatible = "ti,omap2-nand";
		reg = <0 0 4>;  
		interrupt-parent = <&gpmc>;
		interrupts = <0 IRQ_TYPE_NONE>,  
			     <1 IRQ_TYPE_NONE>;	 
		rb-gpios = <&gpmc 0 GPIO_ACTIVE_HIGH>;	 
		ti,nand-xfer-type = "prefetch-dma";
		ti,nand-ecc-opt = "bch16";
		ti,elm-id = <&elm>;
		nand-bus-width = <8>;
		gpmc,device-width = <1>;
		gpmc,sync-clk-ps = <0>;
		gpmc,cs-on-ns = <0>;
		gpmc,cs-rd-off-ns = <40>;  
		gpmc,cs-wr-off-ns = <40>;
		gpmc,adv-on-ns = <0>;   
		gpmc,adv-rd-off-ns = <25>;  
		gpmc,adv-wr-off-ns = <25>;  
		gpmc,we-on-ns = <0>;    
		gpmc,we-off-ns = <20>;  
		gpmc,oe-on-ns = <3>;   
		gpmc,oe-off-ns = <30>;  
		gpmc,access-ns = <30>;  
		gpmc,rd-cycle-ns = <40>;
		gpmc,wr-cycle-ns = <40>;
		gpmc,bus-turnaround-ns = <0>;
		gpmc,cycle2cycle-delay-ns = <0>;
		gpmc,clk-activation-ns = <0>;
		gpmc,wr-access-ns = <40>;
		gpmc,wr-data-mux-bus-ns = <0>;
		#address-cells = <1>;
		#size-cells = <1>;
		partition@0 {
			label = "NAND.SPL";
			reg = <0x00000000 0x00040000>;
		};
		partition@1 {
			label = "NAND.SPL.backup1";
			reg = <0x00040000 0x00040000>;
		};
		partition@2 {
			label = "NAND.SPL.backup2";
			reg = <0x00080000 0x00040000>;
		};
		partition@3 {
			label = "NAND.SPL.backup3";
			reg = <0x000C0000 0x00040000>;
		};
		partition@4 {
			label = "NAND.u-boot-spl-os";
			reg = <0x00100000 0x00080000>;
		};
		partition@5 {
			label = "NAND.u-boot";
			reg = <0x00180000 0x00100000>;
		};
		partition@6 {
			label = "NAND.u-boot-env";
			reg = <0x00280000 0x00040000>;
		};
		partition@7 {
			label = "NAND.u-boot-env.backup1";
			reg = <0x002C0000 0x00040000>;
		};
		partition@8 {
			label = "NAND.kernel";
			reg = <0x00300000 0x00700000>;
		};
		partition@9 {
			label = "NAND.file-system";
			reg = <0x00a00000 0x1f600000>;
		};
	};
};
&epwmss0 {
	status = "okay";
};
&rtc_target {
	status = "disabled";
};
&tscadc {
	status = "okay";
	adc {
		ti,adc-channels = <0 1 2 3 4 5 6 7>;
	};
};
&ecap0 {
		status = "okay";
		pinctrl-names = "default", "sleep";
		pinctrl-0 = <&ecap0_pins_default>;
		pinctrl-1 = <&ecap0_pins_sleep>;
};
&spi0 {
	status = "okay";
	pinctrl-names = "default", "sleep";
	pinctrl-0 = <&spi0_pins_default>;
	pinctrl-1 = <&spi0_pins_sleep>;
	ti,pindir-d0-out-d1-in;
};
&spi1 {
	status = "okay";
	pinctrl-names = "default", "sleep";
	pinctrl-0 = <&spi1_pins_default>;
	pinctrl-1 = <&spi1_pins_sleep>;
	ti,pindir-d0-out-d1-in;
};
&usb2_phy1 {
	status = "okay";
	pinctrl-names = "default", "sleep";
	pinctrl-0 = <&usb2_phy1_default>;
	pinctrl-1 = <&usb2_phy1_sleep>;
};
&usb1 {
	dr_mode = "otg";
	status = "okay";
};
&usb2_phy2 {
	status = "okay";
	pinctrl-names = "default", "sleep";
	pinctrl-0 = <&usb2_phy2_default>;
	pinctrl-1 = <&usb2_phy2_sleep>;
};
&usb2 {
	dr_mode = "host";
	status = "okay";
};
&qspi {
	status = "disabled";	 
	pinctrl-names = "default", "sleep";
	pinctrl-0 = <&qspi1_pins_default>;
	pinctrl-1 = <&qspi1_pins_sleep>;
	spi-max-frequency = <48000000>;
	flash@0 {
		compatible = "mx66l51235l";
		spi-max-frequency = <48000000>;
		reg = <0>;
		spi-cpol;
		spi-cpha;
		spi-tx-bus-width = <1>;
		spi-rx-bus-width = <4>;
		#address-cells = <1>;
		#size-cells = <1>;
		partition@0 {
			label = "QSPI.U_BOOT";
			reg = <0x00000000 0x00080000>;
		};
		partition@1 {
			label = "QSPI.U_BOOT.backup";
			reg = <0x00080000 0x00080000>;
		};
		partition@2 {
			label = "QSPI.U-BOOT-SPL_OS";
			reg = <0x00100000 0x00010000>;
		};
		partition@3 {
			label = "QSPI.U_BOOT_ENV";
			reg = <0x00110000 0x00010000>;
		};
		partition@4 {
			label = "QSPI.U-BOOT-ENV.backup";
			reg = <0x00120000 0x00010000>;
		};
		partition@5 {
			label = "QSPI.KERNEL";
			reg = <0x00130000 0x0800000>;
		};
		partition@6 {
			label = "QSPI.FILESYSTEM";
			reg = <0x00930000 0x36D0000>;
		};
	};
};
&hdq {
	status = "okay";
	pinctrl-names = "default";
	pinctrl-0 = <&hdq_pins>;
};
&dss {
	status = "okay";
	pinctrl-names = "default";
	pinctrl-0 = <&dss_pins>;
	port {
		dpi_out: endpoint {
			remote-endpoint = <&lcd_in>;
			data-lines = <24>;
		};
	};
};
&vpfe1 {
	status = "okay";
	pinctrl-names = "default", "sleep";
	pinctrl-0 = <&vpfe1_pins_default>;
	pinctrl-1 = <&vpfe1_pins_sleep>;
	port {
		vpfe1_ep: endpoint {
			remote-endpoint = <&ov2659_1>;
			ti,am437x-vpfe-interface = <0>;
			bus-width = <8>;
			hsync-active = <0>;
			vsync-active = <0>;
		};
	};
};
&uart0 {
	status = "okay";
	pinctrl-names = "default", "sleep";
	pinctrl-0 = <&uart0_pins_default>;
	pinctrl-1 = <&uart0_pins_sleep>;
};
&mcasp1 {
	#sound-dai-cells = <0>;
	pinctrl-names = "default", "sleep";
	pinctrl-0 = <&mcasp1_pins>;
	pinctrl-1 = <&mcasp1_sleep_pins>;
	status = "okay";
	op-mode = <0>;           
	tdm-slots = <2>;
	serial-dir = <   
		1 2 0 0
	>;
	tx-num-evt = <32>;
	rx-num-evt = <32>;
};
&mux_synctimer32k_ck {
	assigned-clocks = <&mux_synctimer32k_ck>;
	assigned-clock-parents = <&clkdiv32k_ick>;
};
&cpu {
	cpu0-supply = <&dcdc2>;
};
&wkup_m3_ipc {
	firmware-name = "am43x-evm-scale-data.bin";
};
&pruss1_mdio {
	status = "disabled";
};
